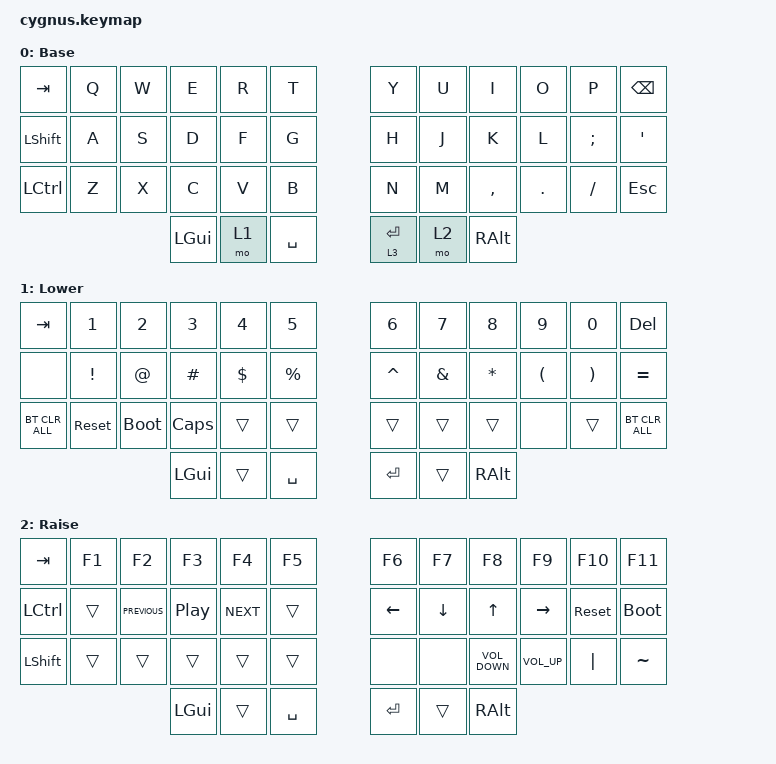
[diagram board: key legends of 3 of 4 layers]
/*
 * Copyright (c) 2020 The ZMK Contributors
 *
 * SPDX-License-Identifier: MIT
 */
#include <dt-bindings/zmk/mouse.h>
#include <behaviors.dtsi>
#include <dt-bindings/zmk/bt.h>
#include <dt-bindings/zmk/keys.h>
#include <dt-bindings/zmk/outputs.h>

&mt {
    tapping-term-ms = <200>;
    flavor = "tap-preferred";
};

&sk {
    release-after-ms = <2000>;
    quick-release;
};

/ {
    combos {
        compatible = "zmk,combos";

        left_bkt {
            bindings = <&kp LBKT>;
            key-positions = <3 2>;
            timeout-ms = <50>;
        };

        right_bkt {
            bindings = <&kp RBKT>;
            key-positions = <6 7>;
            timeout-ms = <50>;
        };

        left_par {
            bindings = <&kp LEFT_PARENTHESIS>;
            key-positions = <12 13>;
            timeout-ms = <50>;
        };

        right_par {
            bindings = <&kp RIGHT_PARENTHESIS>;
            key-positions = <16 17>;
            timeout-ms = <50>;
        };

        left_brace {
            bindings = <&kp LEFT_BRACE>;
            key-positions = <23 22>;
            timeout-ms = <50>;
        };

        right_brace {
            bindings = <&kp RIGHT_BRACE>;
            key-positions = <26 27>;
            timeout-ms = <50>;
        };

        bac {
            bindings = <&kp BACKSLASH>;
            key-positions = <4 5>;
        };

        pipe {
            bindings = <&kp PIPE>;
            key-positions = <14 15>;
        };
    };

    behaviors {
        hm: homerow_mods {
            compatible = "zmk,behavior-hold-tap";
            label = "HOMEROW_MODS";
            #binding-cells = <2>;
            tapping-term-ms = <200>;
            quick_tap_ms = <0>;
            flavor = "tap-preferred";
            bindings = <&kp>, <&kp>;

            quick-tap-ms = <180>;
            global-quick-tap;
        };

        ltq: ltq {
            compatible = "zmk,behavior-hold-tap";
            label = "LTQ";
            #binding-cells = <2>;
            tapping-term-ms = <200>;
            quick_tap_ms = <0>;
            flavor = "hold-preferred";
            bindings = <&mo>, <&kp>;

            quick-tap-ms = <180>;
            global-quick-tap;
        };

        as: as {
            compatible = "zmk,behavior-hold-tap";
            label = "AUTO_SHIFT";
            bindings = <&kp>, <&kp>;

            #binding-cells = <2>;
            tapping-term-ms = <135>;
            quick-tap-ms = <0>;
            flavor = "tap-preferred";
        };
    };

        keymap {
        compatible = "zmk,keymap";

      default_layer {
            // -----------------------------------------------------------------------------------------
            // |  TAB |  Q  |  W  |  E  |  R  |  T  |   |  Y  |  U   |  I  |  O  |  P  | BKSP |
            // | CTRL |  A  |  S  |  D  |  F  |  G  |   |  H  |  J   |  K  |  L  |  ;  |  '   |
            // | SHFT |  Z  |  X  |  C  |  V  |  B  |   |  N  |  M   |  ,  |  .  |  /  | ESC  |
            //                    | GUI | LWR | SPC |   | ENT | RSE  | ALT |

            display-name = "Base";
            bindings = <
&kp TAB           &kp Q  &kp W  &kp E     &kp R  &kp T        &kp Y        &kp U  &kp I      &kp O    &kp P     &kp BSPC
&kp LEFT_SHIFT    &kp A  &kp S  &kp D     &kp F  &kp G        &kp H        &kp J  &kp K      &kp L    &kp SEMI  &kp SQT
&kp LEFT_CONTROL  &kp Z  &kp X  &kp C     &kp V  &kp B        &kp N        &kp M  &kp COMMA  &kp DOT  &kp FSLH  &kp ESC
                                &kp LGUI  &mo 1  &kp SPACE    &lt 3 ENTER  &mo 2  &kp RALT
            >;
        };

        lower_layer {
            // -----------------------------------------------------------------------------------------
            // |  TAB |  1  |  2  |  3  |  4  |  5  |   |  6  |  7  |  8  |  9  |  0  | BKSP |
            // | BTCLR| BT1 | BT2 | BT3 | BT4 | BT5 |   | LFT | DWN |  UP | RGT |     |      |
            // | SHFT |     |     |     |     |     |   |     |     |     |     |     |      |
            //                    | GUI |     | SPC |   | ENT |     | ALT |

            display-name = "Lower";
            bindings = <
&kp TAB         &kp N1           &kp N2       &kp N3        &kp N4      &kp N5         &kp N6     &kp N7         &kp N8        &kp N9                &kp N0                 &kp DELETE
&none           &kp EXCLAMATION  &kp AT_SIGN  &kp HASH      &kp DOLLAR  &kp PERCENT    &kp CARET  &kp AMPERSAND  &kp ASTERISK  &kp LEFT_PARENTHESIS  &kp RIGHT_PARENTHESIS  &kp EQUAL
&bt BT_CLR_ALL  &sys_reset       &bootloader  &kp CAPSLOCK  &trans      &trans         &trans     &trans         &trans        &none                 &trans                 &bt BT_CLR_ALL
                                              &kp LGUI      &trans      &kp SPACE      &kp RET    &trans         &kp RALT
            >;
        };

        raise_layer {
            // -----------------------------------------------------------------------------------------
            // |  TAB |  !  |  @  |  #  |  $  |  %  |   |  ^  |  &  |  *  |  (  |  )  | BKSP |
            // | CTRL |     |     |     |     |     |   |  -  |  =  |  [  |  ]  |  \  |  `   |
            // | SHFT |     |     |     |     |     |   |  _  |  +  |  {  |  }  | "|" |  ~   |
            //                    | GUI |     | SPC |   | ENT |     | ALT |

            display-name = "Raise";
            bindings = <
&kp TAB    &kp F1  &kp F2          &kp F3            &kp F4      &kp F5       &kp F6    &kp F7          &kp F8             &kp F9           &kp F10     &kp F11
&kp LCTRL  &trans  &kp C_PREVIOUS  &kp C_PLAY_PAUSE  &kp C_NEXT  &trans       &kp LEFT  &kp DOWN_ARROW  &kp UP_ARROW       &kp RIGHT        &sys_reset  &bootloader
&kp LSHFT  &trans  &trans          &trans            &trans      &trans       &none     &none           &kp K_VOLUME_DOWN  &kp K_VOLUME_UP  &kp PIPE    &kp TILDE
                                   &kp LGUI          &trans      &kp SPACE    &kp RET   &trans          &kp RALT
            >;
        };

        layer_3 {
            bindings = <
&trans  &trans  &trans  &trans  &trans  &trans    &trans  &trans     &trans  &trans  &trans  &trans
&trans  &trans  &trans  &trans  &trans  &trans    &trans  &kp EQUAL  &trans  &trans  &trans  &trans
&trans  &trans  &trans  &trans  &trans  &trans    &trans  &trans     &trans  &trans  &trans  &trans
                        &trans  &trans  &trans    &trans  &trans     &trans     &trans
            >;

            label = "Flash";
        };
    };

    conditional_layers {
        compatible = "zmk,conditional-layers";

        Flash {
            if-layers = <2 3>;
            then-layer = <5>;
        };
    };
};
